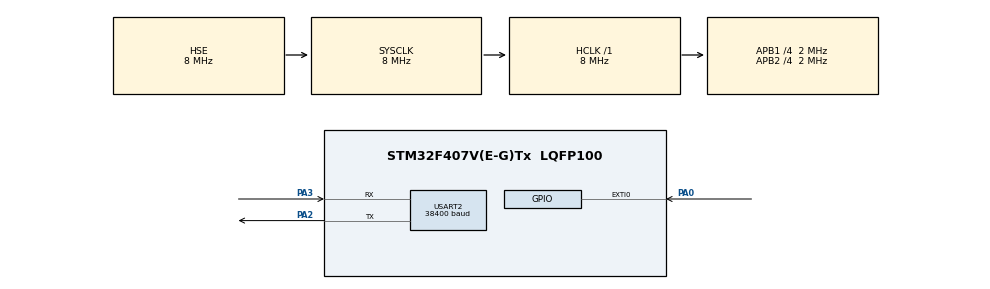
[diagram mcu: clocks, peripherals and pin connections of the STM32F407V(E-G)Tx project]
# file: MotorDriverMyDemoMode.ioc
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Mcu.Family=STM32F4
Mcu.Name=STM32F407V(E-G)Tx
Mcu.Package=LQFP100
NVIC.EXTI0_IRQn=true\:0\:0\:false\:false\:true\:true\:true\:true
NVIC.PriorityGroup=NVIC_PRIORITYGROUP_4
PA0-WKUP.Signal=GPXTI0
PA2.Mode=Asynchronous
PA2.Signal=USART2_TX
PA3.Mode=Asynchronous
PA3.Signal=USART2_RX
PH0-OSC_IN.Mode=HSE-External-Oscillator
PH0-OSC_IN.Signal=RCC_OSC_IN
PH1-OSC_OUT.Mode=HSE-External-Oscillator
PH1-OSC_OUT.Signal=RCC_OSC_OUT
ProjectManager.HeapSize=0x200
ProjectManager.StackSize=0x400
ProjectManager.TargetToolchain=STM32CubeIDE
RCC.48MHZClocksFreq_Value=24000000
RCC.AHBFreq_Value=8000000
RCC.APB1CLKDivider=RCC_HCLK_DIV4
RCC.APB1Freq_Value=2000000
RCC.APB1TimFreq_Value=4000000
RCC.APB2CLKDivider=RCC_HCLK_DIV4
RCC.APB2Freq_Value=2000000
RCC.APB2TimFreq_Value=4000000
RCC.CortexFreq_Value=8000000
RCC.HCLKFreq_Value=8000000
RCC.HSE_VALUE=8000000
RCC.HSI_VALUE=16000000
RCC.LSE_VALUE=32768
RCC.PLLSourceVirtual=RCC_PLLSOURCE_HSE
RCC.SYSCLKFreq_VALUE=8000000
RCC.SYSCLKSource=RCC_SYSCLKSOURCE_HSE
RCC.VCOOutputFreq_Value=96000000
USART2.BaudRate=38400
USART2.VirtualMode=VM_ASYNC
board=custom

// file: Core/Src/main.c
/* USER CODE BEGIN Header */
/**
  ******************************************************************************
  * @file           : main.c
  * @brief          : Main program body
  ******************************************************************************
  * @attention
  *
  * Copyright (c) 2025 STMicroelectronics.
  * All rights reserved.
  *
  * This software is licensed under terms that can be found in the LICENSE file
  * in the root directory of this software component.
  * If no LICENSE file comes with this software, it is provided AS-IS.
  *
  ******************************************************************************
  */
/* USER CODE END Header */
#include "main.h"

/* USER CODE BEGIN Includes */
#include "qik_2s12v10_lib.h"
/* USER CODE END Includes */

UART_HandleTypeDef huart2;

/* USER CODE BEGIN PV */
uint8_t state = 0;
/* USER CODE END PV */

void SystemClock_Config(void);
static void MX_GPIO_Init(void);
static void MX_USART2_UART_Init(void);

int main(void)
{

  /* USER CODE BEGIN 1 */
  uint8_t motor0[3] = {m0Forward, m0Brake, m0Reverse};
  uint8_t motor1[3] = {m1Reverese, m1Brake, m1Forward};
  uint8_t brake = 0;
  /* USER CODE END 1 */

  /* MCU Configuration--------------------------------------------------------*/

  /* Reset of all peripherals, Initializes the Flash interface and the Systick. */
  HAL_Init();

  /* Configure the system clock */
  SystemClock_Config();

  /* Initialize all configured peripherals */
  MX_GPIO_Init();
  MX_USART2_UART_Init();

  /* Infinite loop */
  /* USER CODE BEGIN WHILE */
  while (1)
  {
	  if(state){
		  for(uint8_t i = 0; i< maxSpeed; i+=10 ){
		  		  HAL_UART_Transmit(&huart2, &motor0[0], 1, 20);
		  		  HAL_UART_Transmit(&huart2, &i, 1, 20);
		  		  HAL_Delay(500);
	  	  }
		  HAL_UART_Transmit(&huart2, &motor0[1], 1, 20);
		  HAL_UART_Transmit(&huart2, &brake, 1, 20);
		  brake+=20;
		  if (brake > maxBrake){
			  brake = maxBrake;
		  }
		  for(uint8_t i = maxSpeed; i>= 10; i-=10 ){
			  HAL_UART_Transmit(&huart2, &motor1[0], 1, 20);
			  HAL_UART_Transmit(&huart2, &i, 1, 20);
			  HAL_Delay(500);
		  }
		  HAL_UART_Transmit(&huart2, &motor1[1], 1, 20);
		  HAL_UART_Transmit(&huart2, &brake, 1, 20);

	  }

    /* USER CODE END WHILE */

  }
}

void SystemClock_Config(void)
{
  RCC_OscInitTypeDef RCC_OscInitStruct = {0};
  RCC_ClkInitTypeDef RCC_ClkInitStruct = {0};

  /** Configure the main internal regulator output voltage
  */
  __HAL_RCC_PWR_CLK_ENABLE();
  __HAL_PWR_VOLTAGESCALING_CONFIG(PWR_REGULATOR_VOLTAGE_SCALE1);

  /** Initializes the RCC Oscillators according to the specified parameters
  * in the RCC_OscInitTypeDef structure.
  */
  RCC_OscInitStruct.OscillatorType = RCC_OSCILLATORTYPE_HSE;
  RCC_OscInitStruct.HSEState = RCC_HSE_ON;
  RCC_OscInitStruct.PLL.PLLState = RCC_PLL_NONE;
  if (HAL_RCC_OscConfig(&RCC_OscInitStruct) != HAL_OK)
  {
    Error_Handler();
  }

  /** Initializes the CPU, AHB and APB buses clocks
  */
  RCC_ClkInitStruct.ClockType = RCC_CLOCKTYPE_HCLK|RCC_CLOCKTYPE_SYSCLK
                              |RCC_CLOCKTYPE_PCLK1|RCC_CLOCKTYPE_PCLK2;
  RCC_ClkInitStruct.SYSCLKSource = RCC_SYSCLKSOURCE_HSE;
  RCC_ClkInitStruct.AHBCLKDivider = RCC_SYSCLK_DIV1;
  RCC_ClkInitStruct.APB1CLKDivider = RCC_HCLK_DIV4;
  RCC_ClkInitStruct.APB2CLKDivider = RCC_HCLK_DIV4;

  if (HAL_RCC_ClockConfig(&RCC_ClkInitStruct, FLASH_LATENCY_0) != HAL_OK)
  {
    Error_Handler();
  }
}

static void MX_USART2_UART_Init(void)
{

  huart2.Instance = USART2;
  huart2.Init.BaudRate = 38400;
  huart2.Init.WordLength = UART_WORDLENGTH_8B;
  huart2.Init.StopBits = UART_STOPBITS_1;
  huart2.Init.Parity = UART_PARITY_NONE;
  huart2.Init.Mode = UART_MODE_TX_RX;
  huart2.Init.HwFlowCtl = UART_HWCONTROL_NONE;
  huart2.Init.OverSampling = UART_OVERSAMPLING_16;
  if (HAL_UART_Init(&huart2) != HAL_OK)
  {
    Error_Handler();
  }

}

static void MX_GPIO_Init(void)
{
  GPIO_InitTypeDef GPIO_InitStruct = {0};

  /* GPIO Ports Clock Enable */
  __HAL_RCC_GPIOH_CLK_ENABLE();
  __HAL_RCC_GPIOA_CLK_ENABLE();

  /*Configure GPIO pin : PA0 */
  GPIO_InitStruct.Pin = GPIO_PIN_0;
  GPIO_InitStruct.Mode = GPIO_MODE_IT_RISING;
  GPIO_InitStruct.Pull = GPIO_NOPULL;
  HAL_GPIO_Init(GPIOA, &GPIO_InitStruct);

  /* EXTI interrupt init*/
  HAL_NVIC_SetPriority(EXTI0_IRQn, 0, 0);
  HAL_NVIC_EnableIRQ(EXTI0_IRQn);

}

/* USER CODE BEGIN 4 */

void HAL_GPIO_EXTI_Callback(uint16_t GPIO_Pin)
{
  /* Prevent unused argument(s) compilation warning */
  UNUSED(GPIO_Pin);
  /* NOTE: This function Should not be modified, when the callback is needed,
           the HAL_GPIO_EXTI_Callback could be implemented in the user file
   */
  state ^= 0x1;
}
/* USER CODE END 4 */

void Error_Handler(void)
{
  __disable_irq();
  while (1)
  {
  }
}
